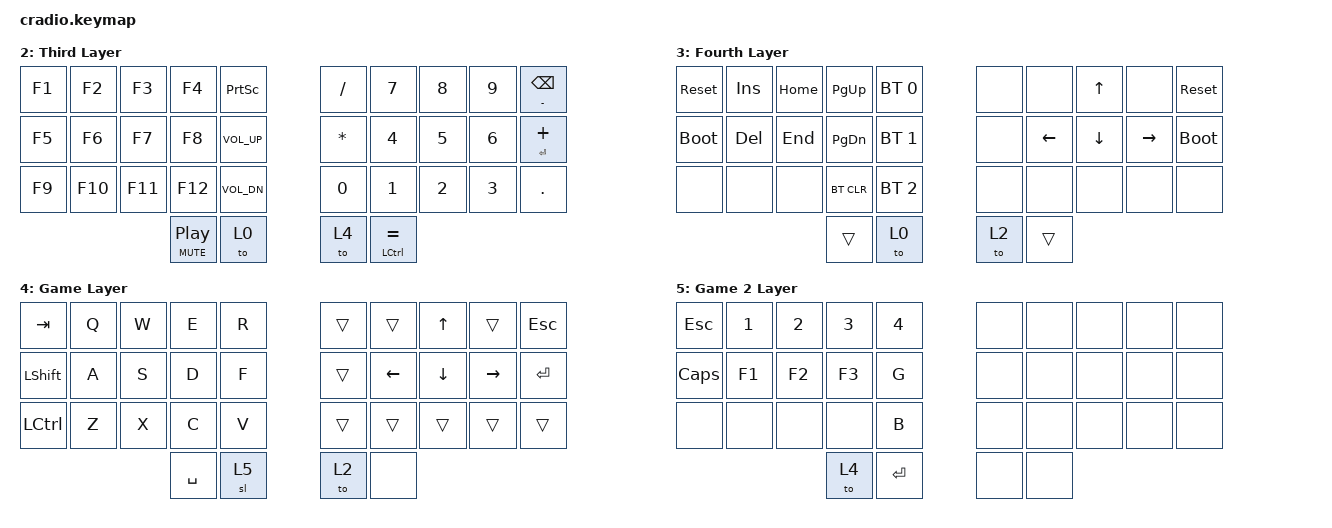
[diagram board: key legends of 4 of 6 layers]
// Copyright (c) 2022 The ZMK Contributors
// SPDX-License-Identifier: MIT

#include <behaviors.dtsi>
#include <dt-bindings/zmk/keys.h>
#include <dt-bindings/zmk/bt.h>

// Home row mods macro
#define HRML(k1,k2) &ht LGUI  k1  &ht LALT k2
#define HRMR(k1,k2) &ht RALT k1  &ht RGUI k2

/ {
    behaviors {
        ht: hold_tap {
            compatible = "zmk,behavior-hold-tap";
            #binding-cells = <2>;
            flavor = "tap-preferred";
            tapping-term-ms = <220>;
            quick-tap-ms = <150>;
            require-prior-idle-ms = <100>;
            bindings = <&kp>, <&kp>;
        };
        lht: mod_tap {
            compatible = "zmk,behavior-hold-tap";
            #binding-cells = <2>;
            flavor = "tap-preferred";
            tapping-term-ms = <200>;
            bindings = <&kp>, <&to>;
            display-name = "Layer-Hold-Tap";
        };
    };

    // conditional_layers {
    //     compatible = "zmk,conditional-layers";
    //     tri_layer {
    //         if-layers = <1 2>;
    //         then-layer = <3>;
    //     };
    // };

    keymap {
        compatible = "zmk,keymap";
        default_layer {
            display-name = "Default Layer";
            bindings = <
        //╭──────────┬──────────┬──────────┬──────────────────┬──────────────────╮   ╭──────────┬──────────┬──────────┬──────────┬──────────╮
        //│  Q       │  W       │  E       │  R				  │  T				 │   │  Y       │  U       │  I       │  O       │  P       │
       &ht LA(LS(Q)) Q  &kp W      &kp E      &kp R				&kp T				   &kp Y      &kp U      &kp I      &kp O      &kp P
        //├──────────┼──────────┼──────────┼──────────────────┼──────────────────┤   ├──────────┼──────────┼──────────┼──────────┼──────────┤
        //│  A       │  S       │  D       │  F				  │  G				 │   │  H       │  J       │  K       │  L       │ ; :      │
            HRML(A,      S)        &kp D      &kp F				&kp G				    &kp H      &kp J      &kp K      HRMR(L,  SEMICOLON)
        //├──────────┼──────────┼──────────┼──────────────────┼──────────────────┤   ├──────────┼──────────┼──────────┼──────────┼──────────┤
        //│  Z       │  X       │  C       │  V				  │  B				 │   │  N       │  M       │ , <      │ . >      │ / ?      │
            &kp Z    &ht LC(X) X &ht LC(C) C  &ht LC(V) V		&kp B				   &kp N      &kp M      &kp COMMA  &kp DOT    &kp FSLH
        //╰──────────┴──────────┴──────────┼──────────────────┼──────────────────┤   ├──────────┼──────────┼──────────┴──────────┴──────────╯
                                            &kp LSHFT           &kp SPACE              &to  1     &ht LCTRL SQT 
        //                                 ╰──────────────────┴──────────────────╯   ╰──────────┴──────────╯
            >;
        };

        right_layer {
            display-name = "Second Layer";
            bindings = <
        //╭──────────────┬──────────┬──────────┬──────────┬──────────╮   ╭──────────┬──────────┬──────────┬──────────┬──────────╮
        //│    ` ~	  !  │  @       │  #       │  $       │    %     │   │    ^     │    &     │    *     │    <=    │  ESC     │
           &ht GRAVE EXCL   &kp AT    &kp HASH   &kp DLLR  &kp PRCNT       &kp CARET  &kp AMPS   &kp ASTRK  &kp BSPC   &kp ESC
        //├──────────────┼──────────┼──────────┼──────────┼──────────┤   ├──────────┼──────────┼──────────┼──────────┼──────────┤
        //│ TAB			 │  {       │  [       │  (       │    - _   │   │ = +      │    )     │    ]     │    }     │\ │  ENTER│
            HRML(TAB		,LBRC)    &kp LBKT   &kp LPAR   &kp MINUS      &kp EQUAL  &kp RPAR   &kp RBKT   &kp RBRC  &ht BSLH ENTER
        //├──────────────┼──────────┼──────────┼──────────┼──────────┤   ├──────────┼──────────┼──────────┼──────────┼──────────┤
        //│ 1			 │  2       │  3       │  4       │  5       │   │    6     │    7     │    8     │    9     │    0     │
           &kp N1		   &kp N2     &kp N3     &kp N4     &kp N5         &kp N6     &kp N7     &kp N8     &kp N9     &kp N0
        //╰──────────────┴──────────┴──────────┼──────────┼──────────┤   ├──────────┼──────────┼──────────┴──────────┴──────────╯
                                           	     &kp LSHFT   &to  0        &to  2    &lht LCTRL 3
        //                                 	   ╰──────────┴──────────╯   ╰──────────┴──────────╯
            >;
        };

        left_layer {
            display-name = "Third Layer";
            bindings = <
        //╭──────────┬──────────┬──────────┬──────────┬──────────╮   ╭──────────┬──────────┬──────────┬──────────┬──────────╮
        //│          │          │          │          │          │   │  /       │  7       │  8       │  9       │  -       │
            &kp F1    &kp F2  	 &kp F3     &kp F4     &kp PSCRN       &kp FSLH   &kp N7  	 &kp N8     &kp N9    &ht MINUS BSPC
        //├──────────┼──────────┼──────────┼──────────┼──────────┤   ├──────────┼──────────┼──────────┼──────────┼──────────┤
        //│          │          │          │          │          │   │  *       │  4       │  5       │  6       │  +  ENTER│
            &kp F5     &kp F6  	  &kp F7     &kp F8     &kp C_VOL_UP  &kp ASTRK   &kp N4  	 &kp N5     &kp N6    &ht ENTER PLUS
        //├──────────┼──────────┼──────────┼──────────┼──────────┤   ├──────────┼──────────┼──────────┼──────────┼──────────┤
        //│          │          │          │          │          │   │  0       │  1       │  2       │  3       │   .      │
            &kp F9     &kp F10 	 &kp F11     &kp F12    &kp C_VOL_DN    &kp N0    &kp N1   	 &kp N2     &kp N3     &kp DOT
        //╰──────────┼──────────┼──────────┴──────────┴──────────┤   ├──────────┼──────────┼──────────┴──────────┴──────────╯
                                &ht C_MUTE C_PLAY_PAUSE  &to  0       &to 4      &ht LCTRL EQUAL
        //                      ╰─────────────────────┴──────────╯   ╰──────────┴──────────╯
            >;
        };

        tri_layer {
            display-name = "Fourth Layer";
            bindings = <
        //╭──────────┬──────────┬──────────┬──────────┬──────────╮   ╭──────────┬──────────┬──────────┬──────────┬──────────╮
        //│ RESET    │          │          │          │PROFILE 0 │   │          │          │          │          │  RESET   │
           &sys_reset  &kp INS    &kp HOME  &kp PG_UP  &bt BT_SEL 0    &none      &none      &kp UP     &none     &sys_reset
        //├──────────┼──────────┼──────────┼──────────┼──────────┤   ├──────────┼──────────┼──────────┼──────────┼──────────┤
        //│BOOTLOADER│          │          │          │PROFILE 1 │   │          │          │          │          │BOOTLOADER│
          &bootloader  &kp DEL    &kp END   &kp PG_DN  &bt BT_SEL 1    &none      &kp LEFT   &kp DOWN  &kp RIGHT  &bootloader
        //├──────────┼──────────┼──────────┼──────────┼──────────┤   ├──────────┼──────────┼──────────┼──────────┼──────────┤
        //│          │          │          │ CLEAR BT │PROFILE 2 │   │          │          │          │          │          │
            &none      &none      &none     &bt BT_CLR &bt BT_SEL 2    &none      &none      &none      &none      &none 
        //╰──────────┴──────────┴──────────┼──────────┼──────────┤   ├──────────┼──────────┼──────────┴──────────┴──────────╯
                                             &trans      &to  0         &to 2     &trans 
        //                                 ╰──────────┴──────────╯   ╰──────────┴──────────╯
            >;
        };

		game_layer {
			display-name = "Game Layer";
			bindings = <
		//╭──────────┬──────────┬──────────┬──────────┬──────────╮   ╭──────────┬──────────┬──────────┬──────────┬──────────╮
		//│  Q       │  W       │  E       │  R       │  T       │   │          │          │          │          │  RESET   │
			&kp TAB		&kp Q      &kp W      &kp E      &kp R         &trans      &trans      &kp UP   &trans    &kp ESC
		//├──────────┼──────────┼──────────┼──────────┼──────────┤   ├──────────┼──────────┼──────────┼──────────┼──────────┤
		//│  A       │  S       │  D       │  F       │  G       │   │          │          │          │          │BOOTLOADER│
			&kp LSHFT	&kp A        &kp S    &kp D      &kp F    	   &trans      &kp LEFT	 &kp DOWN   &kp RIGHT  &kp ENTER
		//├──────────┼──────────┼──────────┼──────────┼──────────┤   ├──────────┼──────────┼──────────┼──────────┼──────────┤
		//│  Z       │  X       │  C       │  V       │  B       │   │          │          │          │          │          │
			&kp LCTRL	&kp Z      &kp X      &kp C      &kp V     	   &trans      &trans      &trans    &trans     &trans 
		//╰──────────┴──────────┴──────────┼──────────┼──────────┤   ├──────────┼──────────┼──────────┴──────────┴──────────╯
											&kp SPACE   &sl  5 		    &to 2     &none
		//                                 ╰──────────┴──────────╯   ╰──────────┴──────────╯
			>;
		};

		game2_layer {
			display-name = "Game 2 Layer";
			bindings = <
		//╭──────────┬──────────┬──────────┬──────────┬──────────╮   ╭──────────┬──────────┬──────────┬──────────┬──────────╮
		//│  ESC     │  1       │  2       │  3       │  4       │   │          │          │          │          │  RESET   │
			&kp ESC    &kp N1		&kp N2    &kp N3      &kp N4       &none   	  &none       &none      &none      &none
		//├──────────┼──────────┼──────────┼──────────┼──────────┤   ├──────────┼──────────┼──────────┼──────────┼──────────┤
		//│  A       │  S       │  D       │  F       │  G       │   │          │          │          │          │BOOTLOADER│
			&kp CAPS   	&kp F1    &kp F2     &kp F3      &kp G   	   &none   	  &none       &none      &none      &none
		//├──────────┼──────────┼──────────┼──────────┼──────────┤   ├──────────┼──────────┼──────────┼──────────┼──────────┤
		//│  Z       │  X       │  C       │  V       │  B       │   │          │          │          │          │          │
			&none	   &none      &none      &none      &kp B     	   &none   	  &none       &none      &none      &none
		//╰──────────┴──────────┴──────────┼──────────┼──────────┤   ├──────────┼──────────┼──────────┴──────────┴──────────╯
											 &to 4     &kp ENTER 	    &none     &none
		//                                 ╰──────────┴──────────╯   ╰──────────┴──────────╯
			>;
		};

    };
};
